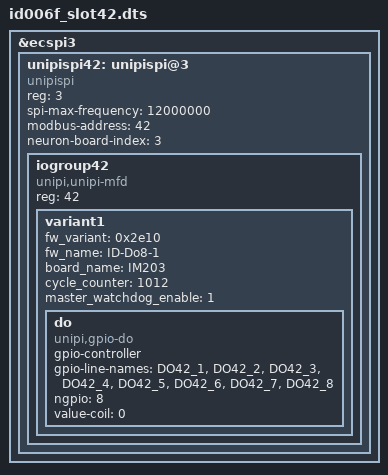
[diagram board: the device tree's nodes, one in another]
/dts-v1/;


/plugin/;

/ {
	fragment@1 {
		
		target = <&ecspi3>;
		__overlay__ {
			status = "okay";
			#address-cells = <1>;
			#size-cells = <0>;

			unipispi42: unipispi@3 {
				compatible = "unipispi";
				reg = <3>;
				status = "okay";
				spi-max-frequency = <12000000>;
				modbus-address = <42>;
				neuron-board-index = <3>;
			};
		};

	};

	fragment@2 {
		target = <&unipispi42>;
		__overlay__ {
			#address-cells = <1>;
			#size-cells = <0>;

			iogroup42 {
				reg = <42>;
				compatible = "unipi,unipi-mfd", "iogroup";
				variant1 { 
					fw_variant = <0x2e10>;
					fw_name = "ID-Do8-1";
					board_name = "IM203";
					cycle_counter = <1012>;
					master_watchdog_enable = <1>;

					do {
						compatible = "unipi,gpio-do";
						gpio-controller;
						#gpio-cells = <2>;
						gpio-line-names = "DO42_1", "DO42_2" , "DO42_3", "DO42_4", "DO42_5", "DO42_6", "DO42_7", "DO42_8";
						ngpio = <8>;
						value-coil = <0>;
					};
				};
			};
		};
	};
};
